AUTOSAR XML (schema 00046)
package /ComponentTypes
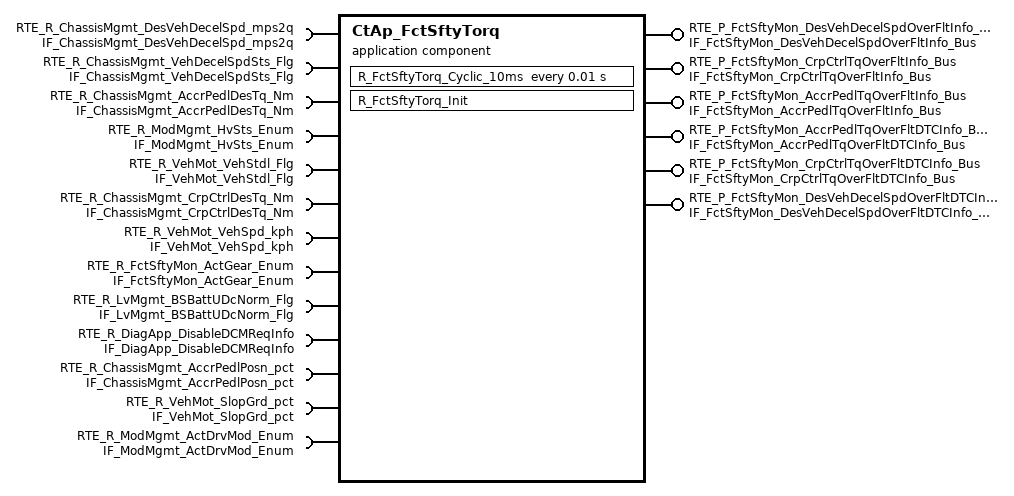
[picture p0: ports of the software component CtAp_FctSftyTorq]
  application sw component type CtAp_FctSftyTorq
    7 x require port:
      RTE_R_ChassisMgmt_DesVehDecelSpd_mps2q: nonqueued-receiver-com-spec{data-element=tec_ChassisMgmt_DesVehDecelSpd_mps2q, filter=data-filter-type=ALWAYS, init-value=0}, required-interface=IF_ChassisMgmt_DesVehDecelSpd_mps2q
      RTE_R_ChassisMgmt_VehDecelSpdSts_Flg: nonqueued-receiver-com-spec{data-element=tec_ChassisMgmt_VehDecelSpdSts_Flg, filter=data-filter-type=ALWAYS, init-value=0}, required-interface=IF_ChassisMgmt_VehDecelSpdSts_Flg
      RTE_R_ChassisMgmt_AccrPedlDesTq_Nm: nonqueued-receiver-com-spec{data-element=tec_ChassisMgmt_AccrPedlDesTq_Nm, filter=data-filter-type=ALWAYS, init-value=0}, required-interface=IF_ChassisMgmt_AccrPedlDesTq_Nm
      RTE_R_ModMgmt_HvSts_Enum: nonqueued-receiver-com-spec{data-element=tec_ModMgmt_HvSts_Enum, filter=data-filter-type=ALWAYS, init-value=0}, required-interface=IF_ModMgmt_HvSts_Enum
      RTE_R_VehMot_VehStdl_Flg: nonqueued-receiver-com-spec{data-element=tec_VehMot_VehStdl_Flg, filter=data-filter-type=ALWAYS, init-value=0}, required-interface=IF_VehMot_VehStdl_Flg
      RTE_R_ChassisMgmt_CrpCtrlDesTq_Nm: nonqueued-receiver-com-spec{data-element=tec_ChassisMgmt_CrpCtrlDesTq_Nm, filter=data-filter-type=ALWAYS, init-value=0}, required-interface=IF_ChassisMgmt_CrpCtrlDesTq_Nm
      RTE_R_VehMot_VehSpd_kph: nonqueued-receiver-com-spec{data-element=tec_VehMot_VehSpd_kph, filter=data-filter-type=ALWAYS, init-value=0}, required-interface=IF_VehMot_VehSpd_kph
    provide port RTE_P_FctSftyMon_DesVehDecelSpdOverFltInfo_Bus: nonqueued-sender-com-spec{data-element=tec_FctSftyMon_DesVehDecelSpdOverFltInfo_Bus, init-value=fields=[FctSftyMon_MonStatDesVehDecelSpdOverFltInfo:0, FctSftyMon_MonResDesVehDecelSpdOverFltInfo:0, FctSftyMon_ErrStatDesVehDecelSpdOverFltInfo:0, FctSftyMon_ErrResDesVehDecelSpdOverFltInfo:0]}, provided-interface=IF_FctSftyMon_DesVehDecelSpdOverFltInfo_Bus
    provide port RTE_P_FctSftyMon_CrpCtrlTqOverFltInfo_Bus: nonqueued-sender-com-spec{data-element=tec_FctSftyMon_CrpCtrlTqOverFltInfo_Bus, init-value=fields=[FctSftyMon_MonStatCrpCtrlTqOverFltInfo:0, FctSftyMon_MonResCrpCtrlTqOverFltInfo:0, FctSftyMon_ErrStatCrpCtrlTqOverFltInfo:0, FctSftyMon_ErrResCrpCtrlTqOverFltInfo:0]}, provided-interface=IF_FctSftyMon_CrpCtrlTqOverFltInfo_Bus
    provide port RTE_P_FctSftyMon_AccrPedlTqOverFltInfo_Bus: nonqueued-sender-com-spec{data-element=tec_FctSftyMon_AccrPedlTqOverFltInfo_Bus, init-value=fields=[FctSftyMon_MonStatAccrPedlTqOverFltInfo:0, FctSftyMon_MonResAccrPedlTqOverFltInfo:0, FctSftyMon_ErrStatAccrPedlTqOverFltInfo:0, FctSftyMon_ErrResAccrPedlTqOverFltInfo:0]}, provided-interface=IF_FctSftyMon_AccrPedlTqOverFltInfo_Bus
    require port RTE_R_FctSftyMon_ActGear_Enum: nonqueued-receiver-com-spec{data-element=tec_FctSftyMon_ActGear_Enum, filter=data-filter-type=ALWAYS, init-value=0}, required-interface=IF_FctSftyMon_ActGear_Enum
    require port RTE_R_LvMgmt_BSBattUDcNorm_Flg: nonqueued-receiver-com-spec{data-element=tec_LvMgmt_BSBattUDcNorm_Flg, filter=data-filter-type=ALWAYS, init-value=0}, required-interface=IF_LvMgmt_BSBattUDcNorm_Flg
    provide port RTE_P_FctSftyMon_AccrPedlTqOverFltDTCInfo_Bus: nonqueued-sender-com-spec{data-element=tec_FctSftyMon_AccrPedlTqOverFltDTCInfo_Bus, init-value=fields=[FctSftyMon_MonStatAccrPedlTqOverFltInfo:0, FctSftyMon_MonResAccrPedlTqOverFltInfo:0, FctSftyMon_ErrStatAccrPedlTqOverFltInfo:0, FctSftyMon_ErrResAccrPedlTqOverFltInfo:0]}, provided-interface=IF_FctSftyMon_AccrPedlTqOverFltDTCInfo_Bus
    provide port RTE_P_FctSftyMon_CrpCtrlTqOverFltDTCInfo_Bus: nonqueued-sender-com-spec{data-element=tec_FctSftyMon_CrpCtrlTqOverFltDTCInfo_Bus, init-value=fields=[FctSftyMon_MonStatCrpCtrlTqOverFltInfo:0, FctSftyMon_MonResCrpCtrlTqOverFltInfo:0, FctSftyMon_ErrStatCrpCtrlTqOverFltInfo:0, FctSftyMon_ErrResCrpCtrlTqOverFltInfo:0]}, provided-interface=IF_FctSftyMon_CrpCtrlTqOverFltDTCInfo_Bus
    provide port RTE_P_FctSftyMon_DesVehDecelSpdOverFltDTCInfo_Bus: nonqueued-sender-com-spec{data-element=tec_FctSftyMon_DesVehDecelSpdOverFltDTCInfo_Bus, init-value=fields=[FctSftyMon_MonStatDesVehDecelSpdOverFltInfo:0, FctSftyMon_MonResDesVehDecelSpdOverFltInfo:0, FctSftyMon_ErrStatDesVehDecelSpdOverFltInfo:0, FctSftyMon_ErrResDesVehDecelSpdOverFltInfo:0]}, provided-interface=IF_FctSftyMon_DesVehDecelSpdOverFltDTCInfo_Bus
    4 x require port:
      RTE_R_DiagApp_DisableDCMReqInfo: nonqueued-receiver-com-spec{data-element=tec_DiagApp_DisableDCMReqInfo, filter=data-filter-type=ALWAYS, init-value=0}, required-interface=IF_DiagApp_DisableDCMReqInfo
      RTE_R_ChassisMgmt_AccrPedlPosn_pct: nonqueued-receiver-com-spec{data-element=tec_ChassisMgmt_AccrPedlPosn_pct, filter=data-filter-type=ALWAYS, init-value=0}, required-interface=IF_ChassisMgmt_AccrPedlPosn_pct
      RTE_R_VehMot_SlopGrd_pct: nonqueued-receiver-com-spec{data-element=tec_VehMot_SlopGrd_pct, filter=data-filter-type=ALWAYS}, required-interface=IF_VehMot_SlopGrd_pct
      RTE_R_ModMgmt_ActDrvMod_Enum: nonqueued-receiver-com-spec{data-element=tec_ModMgmt_ActDrvMod_Enum, filter=data-filter-type=ALWAYS, init-value=0}, required-interface=IF_ModMgmt_ActDrvMod_Enum
    behavior CtAp_FctSftyTorq_InternalBehavior
      timing event TMT_R_FctSftyTorqMon_Cyclic_10ms: start-on-event=R_FctSftyTorq_Cyclic_10ms, period=0.01
      init event CtAp_FctSftyTorq_InitEvent: start-on-event=R_FctSftyTorq_Init
      runnable R_FctSftyTorq_Cyclic_10ms
        data-receive-point-by-arguments:
          13 x access:
            REC_RTE_R_ChassisMgmt_AccrPedlDesTq_Nm_tec_ChassisMgmt_AccrPedlDesTq_Nm: accessed-variable=RTE_R_ChassisMgmt_AccrPedlDesTq_Nm.tec_ChassisMgmt_AccrPedlDesTq_Nm
            REC_RTE_R_ChassisMgmt_CrpCtrlDesTq_Nm_tec_ChassisMgmt_CrpCtrlDesTq_Nm: accessed-variable=RTE_R_ChassisMgmt_CrpCtrlDesTq_Nm.tec_ChassisMgmt_CrpCtrlDesTq_Nm
            REC_RTE_R_ChassisMgmt_DesVehDecelSpd_mps2q_tec_ChassisMgmt_DesVehDecelSpd_mps2q: accessed-variable=RTE_R_ChassisMgmt_DesVehDecelSpd_mps2q.tec_ChassisMgmt_DesVehDecelSpd_mps2q
            REC_RTE_R_ChassisMgmt_VehDecelSpdSts_Flg_tec_ChassisMgmt_VehDecelSpdSts_Flg: accessed-variable=RTE_R_ChassisMgmt_VehDecelSpdSts_Flg.tec_ChassisMgmt_VehDecelSpdSts_Flg
            REC_RTE_R_FctSftyMon_ActGear_Enum_tec_FctSftyMon_ActGear_Enum: accessed-variable=RTE_R_FctSftyMon_ActGear_Enum.tec_FctSftyMon_ActGear_Enum
            REC_RTE_R_LvMgmt_BSBattUDcNorm_Flg_tec_LvMgmt_BSBattUDcNorm_Flg: accessed-variable=RTE_R_LvMgmt_BSBattUDcNorm_Flg.tec_LvMgmt_BSBattUDcNorm_Flg
            REC_RTE_R_ModMgmt_HvSts_Enum_tec_ModMgmt_HvSts_Enum: accessed-variable=RTE_R_ModMgmt_HvSts_Enum.tec_ModMgmt_HvSts_Enum
            REC_RTE_R_VehMot_VehSpd_kph_tec_VehMot_VehSpd_kph: accessed-variable=RTE_R_VehMot_VehSpd_kph.tec_VehMot_VehSpd_kph
            REC_RTE_R_VehMot_VehStdl_Flg_tec_VehMot_VehStdl_Flg: accessed-variable=RTE_R_VehMot_VehStdl_Flg.tec_VehMot_VehStdl_Flg
            REC_RTE_R_DiagApp_DisableDCMReqInfo_tec_DiagApp_DisableDCMReqInfo: accessed-variable=RTE_R_DiagApp_DisableDCMReqInfo.tec_DiagApp_DisableDCMReqInfo
            REC_RTE_R_ChassisMgmt_AccrPedlPosn_pct_tec_ChassisMgmt_AccrPedlPosn_pct: accessed-variable=RTE_R_ChassisMgmt_AccrPedlPosn_pct.tec_ChassisMgmt_AccrPedlPosn_pct
            REC_RTE_R_VehMot_SlopGrd_pct_tec_VehMot_SlopGrd_pct: accessed-variable=RTE_R_VehMot_SlopGrd_pct.tec_VehMot_SlopGrd_pct
            REC_RTE_R_ModMgmt_ActDrvMod_Enum_tec_ModMgmt_ActDrvMod_Enum: accessed-variable=RTE_R_ModMgmt_ActDrvMod_Enum.tec_ModMgmt_ActDrvMod_Enum
        data-send-points:
          6 x access:
            SEND_RTE_P_FctSftyMon_AccrPedlTqOverFltInfo_Bus_tec_FctSftyMon_AccrPedlTqOverFltInfo_Bus: accessed-variable=RTE_P_FctSftyMon_AccrPedlTqOverFltInfo_Bus.tec_FctSftyMon_AccrPedlTqOverFltInfo_Bus
            SEND_RTE_P_FctSftyMon_CrpCtrlTqOverFltInfo_Bus_tec_FctSftyMon_CrpCtrlTqOverFltInfo_Bus: accessed-variable=RTE_P_FctSftyMon_CrpCtrlTqOverFltInfo_Bus.tec_FctSftyMon_CrpCtrlTqOverFltInfo_Bus
            SEND_RTE_P_FctSftyMon_DesVehDecelSpdOverFltInfo_Bus_tec_FctSftyMon_DesVehDecelSpdOverFltInfo_Bus: accessed-variable=RTE_P_FctSftyMon_DesVehDecelSpdOverFltInfo_Bus.tec_FctSftyMon_DesVehDecelSpdOverFltInfo_Bus
            SEND_RTE_P_FctSftyMon_AccrPedlTqOverFltDTCInfo_Bus_tec_FctSftyMon_AccrPedlTqOverFltDTCInfo_Bus: accessed-variable=RTE_P_FctSftyMon_AccrPedlTqOverFltDTCInfo_Bus.tec_FctSftyMon_AccrPedlTqOverFltDTCInfo_Bus
            SEND_RTE_P_FctSftyMon_CrpCtrlTqOverFltDTCInfo_Bus_tec_FctSftyMon_CrpCtrlTqOverFltDTCInfo_Bus: accessed-variable=RTE_P_FctSftyMon_CrpCtrlTqOverFltDTCInfo_Bus.tec_FctSftyMon_CrpCtrlTqOverFltDTCInfo_Bus
            SEND_RTE_P_FctSftyMon_DesVehDecelSpdOverFltDTCInfo_Bus_tec_FctSftyMon_DesVehDecelSpdOverFltDTCInfo_Bus: accessed-variable=RTE_P_FctSftyMon_DesVehDecelSpdOverFltDTCInfo_Bus.tec_FctSftyMon_DesVehDecelSpdOverFltDTCInfo_Bus
      runnable R_FctSftyTorq_Init
  swc implementation CtAp_FctSftyTorq_Implementation: behavior=CtAp_FctSftyTorq_InternalBehavior
